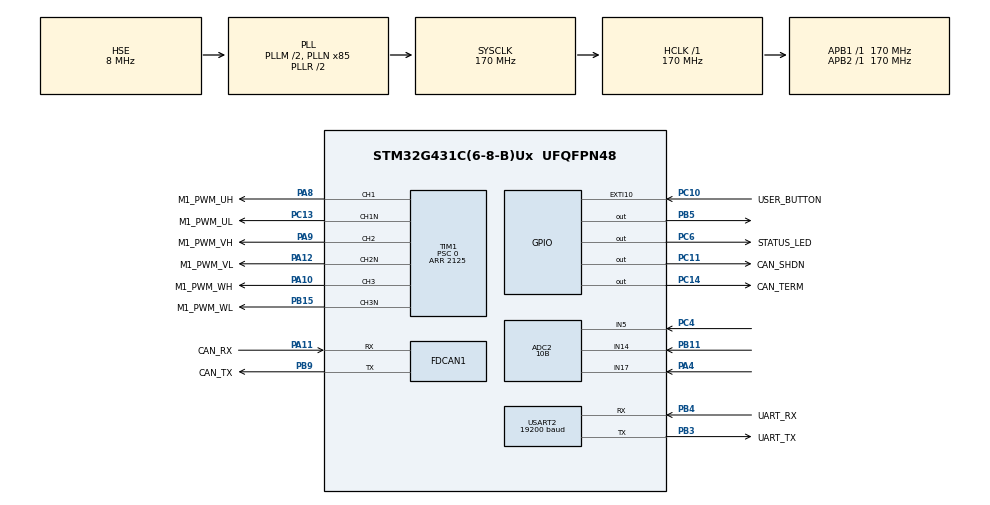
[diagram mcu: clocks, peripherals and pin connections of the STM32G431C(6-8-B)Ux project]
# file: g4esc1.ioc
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ADC2.Channel-0\#ChannelRegularConversion=ADC_CHANNEL_17
ADC2.Channel-1\#ChannelRegularConversion=ADC_CHANNEL_5
ADC2.Channel-2\#ChannelRegularConversion=ADC_CHANNEL_14
ADC2.ContinuousConvMode=ENABLE
ADC2.DMAContinuousRequests=ENABLE
ADC2.EOCSelection=ADC_EOC_SEQ_CONV
ADC2.NbrOfConversion=3
ADC2.NbrOfConversionFlag=1
ADC2.OffsetNumber-0\#ChannelRegularConversion=ADC_OFFSET_NONE
ADC2.OffsetNumber-1\#ChannelRegularConversion=ADC_OFFSET_NONE
ADC2.OffsetNumber-2\#ChannelRegularConversion=ADC_OFFSET_NONE
ADC2.Rank-0\#ChannelRegularConversion=1
ADC2.Rank-1\#ChannelRegularConversion=2
ADC2.Rank-2\#ChannelRegularConversion=3
ADC2.Resolution=ADC_RESOLUTION_10B
ADC2.SamplingTime-0\#ChannelRegularConversion=ADC_SAMPLETIME_12CYCLES_5
ADC2.SamplingTime-1\#ChannelRegularConversion=ADC_SAMPLETIME_12CYCLES_5
ADC2.SamplingTime-2\#ChannelRegularConversion=ADC_SAMPLETIME_12CYCLES_5
Dma.ADC2.2.Direction=DMA_PERIPH_TO_MEMORY
Dma.ADC2.2.EventEnable=DISABLE
Dma.ADC2.2.Instance=DMA1_Channel3
Dma.ADC2.2.MemDataAlignment=DMA_MDATAALIGN_HALFWORD
Dma.ADC2.2.MemInc=DMA_MINC_ENABLE
Dma.ADC2.2.Mode=DMA_CIRCULAR
Dma.ADC2.2.PeriphDataAlignment=DMA_PDATAALIGN_HALFWORD
Dma.ADC2.2.PeriphInc=DMA_PINC_DISABLE
Dma.ADC2.2.Polarity=HAL_DMAMUX_REQ_GEN_RISING
Dma.ADC2.2.Priority=DMA_PRIORITY_LOW
Dma.ADC2.2.RequestNumber=1
Dma.ADC2.2.SignalID=NONE
Dma.ADC2.2.SyncEnable=DISABLE
Dma.ADC2.2.SyncPolarity=HAL_DMAMUX_SYNC_NO_EVENT
Dma.ADC2.2.SyncRequestNumber=1
Dma.ADC2.2.SyncSignalID=NONE
Dma.Request0=USART2_RX
Dma.Request1=USART2_TX
Dma.Request2=ADC2
Dma.USART2_RX.0.Direction=DMA_PERIPH_TO_MEMORY
Dma.USART2_RX.0.EventEnable=DISABLE
Dma.USART2_RX.0.Instance=DMA1_Channel1
Dma.USART2_RX.0.MemDataAlignment=DMA_MDATAALIGN_BYTE
Dma.USART2_RX.0.MemInc=DMA_MINC_ENABLE
Dma.USART2_RX.0.Mode=DMA_CIRCULAR
Dma.USART2_RX.0.PeriphDataAlignment=DMA_PDATAALIGN_BYTE
Dma.USART2_RX.0.PeriphInc=DMA_PINC_DISABLE
Dma.USART2_RX.0.Polarity=HAL_DMAMUX_REQ_GEN_RISING
Dma.USART2_RX.0.Priority=DMA_PRIORITY_LOW
Dma.USART2_RX.0.RequestNumber=1
Dma.USART2_RX.0.SignalID=NONE
Dma.USART2_RX.0.SyncEnable=DISABLE
Dma.USART2_RX.0.SyncPolarity=HAL_DMAMUX_SYNC_NO_EVENT
Dma.USART2_RX.0.SyncRequestNumber=1
Dma.USART2_RX.0.SyncSignalID=NONE
Dma.USART2_TX.1.Direction=DMA_MEMORY_TO_PERIPH
Dma.USART2_TX.1.EventEnable=DISABLE
Dma.USART2_TX.1.Instance=DMA1_Channel2
Dma.USART2_TX.1.MemDataAlignment=DMA_MDATAALIGN_BYTE
Dma.USART2_TX.1.MemInc=DMA_MINC_ENABLE
Dma.USART2_TX.1.Mode=DMA_NORMAL
Dma.USART2_TX.1.PeriphDataAlignment=DMA_PDATAALIGN_BYTE
Dma.USART2_TX.1.PeriphInc=DMA_PINC_DISABLE
Dma.USART2_TX.1.Polarity=HAL_DMAMUX_REQ_GEN_RISING
Dma.USART2_TX.1.Priority=DMA_PRIORITY_LOW
Dma.USART2_TX.1.RequestNumber=1
Dma.USART2_TX.1.SignalID=NONE
Dma.USART2_TX.1.SyncEnable=DISABLE
Dma.USART2_TX.1.SyncPolarity=HAL_DMAMUX_SYNC_NO_EVENT
Dma.USART2_TX.1.SyncRequestNumber=1
Dma.USART2_TX.1.SyncSignalID=NONE
FDCAN1.AutoRetransmission=ENABLE
FDCAN1.CalculateBaudRateNominal=999999
FDCAN1.CalculateTimeBitNominal=1000
FDCAN1.CalculateTimeQuantumNominal=58.82352941176471
FDCAN1.NominalPrescaler=10
FDCAN1.NominalTimeSeg1=13
FDCAN1.NominalTimeSeg2=3
Mcu.Family=STM32G4
Mcu.Name=STM32G431C(6-8-B)Ux
Mcu.Package=UFQFPN48
NVIC.ADC1_2_IRQn=true\:0\:0\:false\:false\:true\:true\:true\:true
NVIC.DMA1_Channel1_IRQn=true\:3\:0\:true\:false\:true\:false\:true\:true
NVIC.DMA1_Channel2_IRQn=true\:3\:0\:true\:false\:true\:false\:true\:true
NVIC.DMA1_Channel3_IRQn=true\:0\:0\:false\:false\:true\:false\:true\:true
NVIC.EXTI15_10_IRQn=true\:4\:0\:true\:false\:true\:true\:true\:true
NVIC.FDCAN1_IT0_IRQn=true\:3\:0\:true\:false\:true\:true\:true\:true
NVIC.PriorityGroup=NVIC_PRIORITYGROUP_4
NVIC.TIM1_BRK_TIM15_IRQn=true\:1\:0\:true\:false\:true\:true\:true\:true
NVIC.TIM1_UP_TIM16_IRQn=true\:0\:0\:true\:false\:true\:true\:true\:true
NVIC.TIM6_DAC_IRQn=true\:3\:0\:true\:false\:true\:true\:true\:true
NVIC.USART2_IRQn=true\:3\:0\:true\:false\:true\:true\:true\:true
PA0.GPIO_Label=M1_BUS_VOLTAGE
PA0.Signal=ADC1_IN1
PA1.GPIO_Label=BEMF_U
PA1.Signal=SharedAnalog_PA1
PA10.GPIO_Label=M1_PWM_WH
PA10.GPIO_PuPd=GPIO_PULLDOWN
PA10.GPIO_Speed=GPIO_SPEED_FREQ_HIGH
PA10.Signal=S_TIM1_CH3
PA11.GPIO_Label=CAN_RX
PA11.Mode=FDCAN_Activate
PA11.Signal=FDCAN1_RX
PA12.GPIO_Label=M1_PWM_VL
PA12.GPIO_PuPd=GPIO_PULLDOWN
PA12.GPIO_Speed=GPIO_SPEED_FREQ_HIGH
PA12.Mode=PWM Generation2 CH2 CH2N
PA12.Signal=TIM1_CH2N
PA13.GPIO_Label=TMS
PA13.Mode=Serial_Wire
PA13.Signal=SYS_JTMS-SWDIO
PA14.GPIO_Label=TCK
PA14.Mode=Serial_Wire
PA14.Signal=SYS_JTCK-SWCLK
PA4.Mode=IN17-Single-Ended
PA4.Signal=ADC2_IN17
PA7.GPIO_Label=BEMF_V
PA7.Signal=SharedAnalog_PA7
PA8.GPIO_Label=M1_PWM_UH
PA8.GPIO_PuPd=GPIO_PULLDOWN
PA8.GPIO_Speed=GPIO_SPEED_FREQ_HIGH
PA8.Signal=S_TIM1_CH1
PA9.GPIO_Label=M1_PWM_VH
PA9.GPIO_PuPd=GPIO_PULLDOWN
PA9.GPIO_Speed=GPIO_SPEED_FREQ_HIGH
PA9.Signal=S_TIM1_CH2
PB0.GPIO_Label=BEMF_W
PB0.Signal=SharedAnalog_PB0
PB11.Mode=IN14-Single-Ended
PB11.Signal=ADC2_IN14
PB14.GPIO_Label=M1_TEMPERATURE
PB14.Signal=ADC1_IN5
PB15.GPIO_Label=M1_PWM_WL
PB15.GPIO_PuPd=GPIO_PULLDOWN
PB15.GPIO_Speed=GPIO_SPEED_FREQ_HIGH
PB15.Mode=PWM Generation3 CH3 CH3N
PB15.Signal=TIM1_CH3N
PB3.GPIO_Label=UART_TX
PB3.GPIO_Mode=GPIO_MODE_AF_PP
PB3.GPIO_PuPd=GPIO_NOPULL
PB3.GPIO_Speed=GPIO_SPEED_FREQ_LOW
PB3.Mode=Asynchronous
PB3.Signal=USART2_TX
PB4.GPIO_Label=UART_RX
PB4.GPIO_Mode=GPIO_MODE_AF_PP
PB4.GPIO_PuPd=GPIO_NOPULL
PB4.GPIO_Speed=GPIO_SPEED_FREQ_LOW
PB4.Mode=Asynchronous
PB4.Signal=USART2_RX
PB5.Signal=GPIO_Output
PB9.GPIO_Label=CAN_TX
PB9.Mode=FDCAN_Activate
PB9.Signal=FDCAN1_TX
PC10.GPIO_Label=USER_BUTTON
PC10.GPIO_ModeDefaultEXTI=GPIO_MODE_IT_FALLING
PC10.GPIO_PuPd=GPIO_NOPULL
PC10.Signal=GPXTI10
PC11.GPIO_Label=CAN_SHDN
PC11.Signal=GPIO_Output
PC13.GPIO_Label=M1_PWM_UL
PC13.GPIO_PuPd=GPIO_PULLDOWN
PC13.GPIO_Speed=GPIO_SPEED_FREQ_HIGH
PC13.Mode=PWM Generation1 CH1 CH1N
PC13.Signal=TIM1_CH1N
PC14-OSC32_IN.GPIO_Label=CAN_TERM
PC14-OSC32_IN.Signal=GPIO_Output
PC4.Mode=IN5-Single-Ended
PC4.Signal=ADC2_IN5
PC6.GPIO_Label=STATUS_LED
PC6.Signal=GPIO_Output
PF0-OSC_IN.Mode=HSE-External-Oscillator
PF0-OSC_IN.Signal=RCC_OSC_IN
PF1-OSC_OUT.Mode=HSE-External-Oscillator
PF1-OSC_OUT.Signal=RCC_OSC_OUT
ProjectManager.HeapSize=0x200
ProjectManager.StackSize=0x400
ProjectManager.TargetToolchain=STM32CubeIDE
RCC.ADC12CLockSelection=RCC_ADC12CLKSOURCE_PLL
RCC.ADC12Freq_Value=42500000
RCC.AHBFreq_Value=170000000
RCC.APB1Freq_Value=170000000
RCC.APB1TimFreq_Value=170000000
RCC.APB2Freq_Value=170000000
RCC.APB2TimFreq_Value=170000000
RCC.CK48CLockSelection=RCC_USBCLKSOURCE_PLL
RCC.CortexFreq_Value=170000000
RCC.EXTERNAL_CLOCK_VALUE=12288000
RCC.EnbaleCSS=true
RCC.HCLKFreq_Value=170000000
RCC.HSE_VALUE=8000000
RCC.HSI48_VALUE=48000000
RCC.HSI_VALUE=16000000
RCC.LSE_VALUE=32768
RCC.PLLM=RCC_PLLM_DIV2
RCC.PLLN=85
RCC.PLLP=RCC_PLLP_DIV8
RCC.PLLSourceVirtual=RCC_PLLSOURCE_HSE
RCC.PREFETCH_ENABLE=1
RCC.SYSCLKFreq_VALUE=170000000
RCC.SYSCLKSource=RCC_SYSCLKSOURCE_PLLCLK
RCC.USBFreq_Value=170000000
RCC.VCOOutputFreq_Value=340000000
SH.S_TIM1_CH1.0=TIM1_CH1,PWM Generation1 CH1 CH1N
SH.S_TIM1_CH2.0=TIM1_CH2,PWM Generation2 CH2 CH2N
SH.S_TIM1_CH3.0=TIM1_CH3,PWM Generation3 CH3 CH3N
SH.SharedAnalog_PA1.0=COMP1_INP
SH.SharedAnalog_PA7.0=COMP2_INP
SH.SharedAnalog_PB0.0=COMP4_INP
TIM1.AutoReloadPreload=TIM_AUTORELOAD_PRELOAD_DISABLE
TIM1.AutomaticOutput=TIM_AUTOMATICOUTPUT_DISABLE
TIM1.Break2Filter=3
TIM1.Break2Polarity=TIM_BREAK2POLARITY_HIGH
TIM1.Break2State=TIM_BREAK2_DISABLE
TIM1.BreakFilter=3
TIM1.BreakPolarity=TIM_BREAKPOLARITY_HIGH
TIM1.BreakState=TIM_BREAK_ENABLE
TIM1.Channel=TIM_CHANNEL_4
TIM1.Channel-PWM\ Generation1\ CH1\ CH1N=TIM_CHANNEL_1
TIM1.Channel-PWM\ Generation2\ CH2\ CH2N=TIM_CHANNEL_2
TIM1.Channel-PWM\ Generation3\ CH3\ CH3N=TIM_CHANNEL_3
TIM1.Channel-PWM\ Generation4\ No\ Output=TIM_CHANNEL_4
TIM1.ClearInputSource=TIM_CLEARINPUTSOURCE_NONE
TIM1.ClockDivision=TIM_CLOCKDIVISION_DIV2
TIM1.CounterMode=TIM_COUNTERMODE_CENTERALIGNED1
TIM1.DeadTime=68
TIM1.LockLevel=TIM_LOCKLEVEL_OFF
TIM1.OC1Preload_PWM=ENABLE
TIM1.OC2Preload_PWM=ENABLE
TIM1.OC3Preload_PWM=ENABLE
TIM1.OC4Preload_PWM=ENABLE
TIM1.OCFastMode_PWM=TIM_OCFAST_DISABLE
TIM1.OCIdleState_1=TIM_OCIDLESTATE_RESET
TIM1.OCIdleState_2=TIM_OCIDLESTATE_RESET
TIM1.OCIdleState_3=TIM_OCIDLESTATE_RESET
TIM1.OCIdleState_4=TIM_OCIDLESTATE_RESET
TIM1.OCMode_PWM-PWM\ Generation1\ CH1\ CH1N=TIM_OCMODE_PWM1
TIM1.OCMode_PWM-PWM\ Generation2\ CH2\ CH2N=TIM_OCMODE_PWM1
TIM1.OCMode_PWM-PWM\ Generation3\ CH3\ CH3N=TIM_OCMODE_PWM1
TIM1.OCMode_PWM-PWM\ Generation4\ No\ Output=TIM_OCMODE_PWM2
TIM1.OCNIdleState_1=TIM_OCNIDLESTATE_RESET
TIM1.OCNIdleState_2=TIM_OCNIDLESTATE_RESET
TIM1.OCNIdleState_3=TIM_OCNIDLESTATE_RESET
TIM1.OCNPolarity_1=TIM_OCNPOLARITY_HIGH
TIM1.OCNPolarity_2=TIM_OCNPOLARITY_HIGH
TIM1.OCNPolarity_3=TIM_OCNPOLARITY_HIGH
TIM1.OCPolarity_1=TIM_OCPOLARITY_HIGH
TIM1.OCPolarity_2=TIM_OCPOLARITY_HIGH
TIM1.OCPolarity_3=TIM_OCPOLARITY_HIGH
TIM1.OCPolarity_4=TIM_OCPOLARITY_HIGH
TIM1.OffStateIDLEMode=TIM_OSSI_ENABLE
TIM1.OffStateRunMode=TIM_OSSR_ENABLE
TIM1.PeriodNoDither=2125
TIM1.Prescaler=0
TIM1.PulseNoDither_1=0
TIM1.PulseNoDither_2=0
TIM1.PulseNoDither_3=0
TIM1.PulseNoDither_4=1
TIM1.RepetitionCounter=1
TIM1.SourceBRK2DigInput=TIM_BREAKINPUTSOURCE_DISABLE
TIM1.SourceBRKCOMP1=TIM_BREAKINPUTSOURCE_DISABLE
TIM1.SourceBRKCOMP2=TIM_BREAKINPUTSOURCE_DISABLE
TIM1.SourceBRKCOMP4=TIM_BREAKINPUTSOURCE_DISABLE
TIM1.SourceBRKDigInput=TIM_BREAKINPUTSOURCE_DISABLE
TIM1.TIM_MasterOutputTrigger=TIM_TRGO_OC4REF
TIM1.TIM_MasterOutputTrigger2=TIM_TRGO2_RESET
TIM6.Period=999
TIM6.Prescaler=169
USART2.BaudRate=19200
USART2.VirtualMode-Asynchronous=VM_ASYNC
USART2.WordLength=WORDLENGTH_8B
VP_SYS_VS_DBSignals.Mode=DisableDeadBatterySignals
VP_TIM1_VS_ClockSourceINT.Mode=Internal
VP_TIM1_VS_no_output4.Mode=PWM Generation4 No Output
VP_TIM6_VS_ClockSourceINT.Mode=Enable_Timer
board=custom

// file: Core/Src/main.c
/* USER CODE BEGIN Header */
/**
  ******************************************************************************
  * @file           : main.c
  * @brief          : Main program body
  ******************************************************************************
  * @attention
  *
  * Copyright (c) 2026 STMicroelectronics.
  * All rights reserved.
  *
  * This software is licensed under terms that can be found in the LICENSE file
  * in the root directory of this software component.
  * If no LICENSE file comes with this software, it is provided AS-IS.
  *
  ******************************************************************************
  */
/* USER CODE END Header */
#include "main.h"

/* USER CODE BEGIN Includes */
#include <platform.h>
/* USER CODE END Includes */

ADC_HandleTypeDef hadc2;
DMA_HandleTypeDef hdma_adc2;

FDCAN_HandleTypeDef hfdcan1;

TIM_HandleTypeDef htim1;
TIM_HandleTypeDef htim6;

UART_HandleTypeDef huart2;
DMA_HandleTypeDef hdma_usart2_rx;
DMA_HandleTypeDef hdma_usart2_tx;

void SystemClock_Config(void);
static void MX_GPIO_Init(void);
static void MX_DMA_Init(void);
static void MX_FDCAN1_Init(void);
static void MX_TIM1_Init(void);
static void MX_TIM6_Init(void);
static void MX_USART2_UART_Init(void);
static void MX_ADC2_Init(void);

int main(void)
{

  /* MCU Configuration--------------------------------------------------------*/

  /* Reset of all peripherals, Initializes the Flash interface and the Systick. */
  HAL_Init();

  /* Configure the system clock */
  SystemClock_Config();

  /* Initialize all configured peripherals */
  MX_GPIO_Init();
  MX_DMA_Init();
  MX_FDCAN1_Init();
  MX_TIM1_Init();
  MX_TIM6_Init();
  MX_USART2_UART_Init();
  MX_ADC2_Init();
  /* USER CODE BEGIN 2 */
  platform_setup();
  /* USER CODE END 2 */

  /* Infinite loop */
  while (1)
  {

  }
}

void SystemClock_Config(void)
{
  RCC_OscInitTypeDef RCC_OscInitStruct = {0};
  RCC_ClkInitTypeDef RCC_ClkInitStruct = {0};

  /** Configure the main internal regulator output voltage
  */
  HAL_PWREx_ControlVoltageScaling(PWR_REGULATOR_VOLTAGE_SCALE1_BOOST);

  /** Initializes the RCC Oscillators according to the specified parameters
  * in the RCC_OscInitTypeDef structure.
  */
  RCC_OscInitStruct.OscillatorType = RCC_OSCILLATORTYPE_HSE;
  RCC_OscInitStruct.HSEState = RCC_HSE_ON;
  RCC_OscInitStruct.PLL.PLLState = RCC_PLL_ON;
  RCC_OscInitStruct.PLL.PLLSource = RCC_PLLSOURCE_HSE;
  RCC_OscInitStruct.PLL.PLLM = RCC_PLLM_DIV2;
  RCC_OscInitStruct.PLL.PLLN = 85;
  RCC_OscInitStruct.PLL.PLLP = RCC_PLLP_DIV8;
  RCC_OscInitStruct.PLL.PLLQ = RCC_PLLQ_DIV2;
  RCC_OscInitStruct.PLL.PLLR = RCC_PLLR_DIV2;
  if (HAL_RCC_OscConfig(&RCC_OscInitStruct) != HAL_OK)
  {
    Error_Handler();
  }

  /** Initializes the CPU, AHB and APB buses clocks
  */
  RCC_ClkInitStruct.ClockType = RCC_CLOCKTYPE_HCLK|RCC_CLOCKTYPE_SYSCLK
                              |RCC_CLOCKTYPE_PCLK1|RCC_CLOCKTYPE_PCLK2;
  RCC_ClkInitStruct.SYSCLKSource = RCC_SYSCLKSOURCE_PLLCLK;
  RCC_ClkInitStruct.AHBCLKDivider = RCC_SYSCLK_DIV1;
  RCC_ClkInitStruct.APB1CLKDivider = RCC_HCLK_DIV1;
  RCC_ClkInitStruct.APB2CLKDivider = RCC_HCLK_DIV1;

  if (HAL_RCC_ClockConfig(&RCC_ClkInitStruct, FLASH_LATENCY_4) != HAL_OK)
  {
    Error_Handler();
  }

  /** Enables the Clock Security System
  */
  HAL_RCC_EnableCSS();
}

static void MX_ADC2_Init(void)
{

  ADC_ChannelConfTypeDef sConfig = {0};

  /** Common config
  */
  hadc2.Instance = ADC2;
  hadc2.Init.ClockPrescaler = ADC_CLOCK_SYNC_PCLK_DIV4;
  hadc2.Init.Resolution = ADC_RESOLUTION_10B;
  hadc2.Init.DataAlign = ADC_DATAALIGN_RIGHT;
  hadc2.Init.GainCompensation = 0;
  hadc2.Init.ScanConvMode = ADC_SCAN_ENABLE;
  hadc2.Init.EOCSelection = ADC_EOC_SEQ_CONV;
  hadc2.Init.LowPowerAutoWait = DISABLE;
  hadc2.Init.ContinuousConvMode = ENABLE;
  hadc2.Init.NbrOfConversion = 3;
  hadc2.Init.DiscontinuousConvMode = DISABLE;
  hadc2.Init.ExternalTrigConv = ADC_SOFTWARE_START;
  hadc2.Init.ExternalTrigConvEdge = ADC_EXTERNALTRIGCONVEDGE_NONE;
  hadc2.Init.DMAContinuousRequests = ENABLE;
  hadc2.Init.Overrun = ADC_OVR_DATA_PRESERVED;
  hadc2.Init.OversamplingMode = DISABLE;
  if (HAL_ADC_Init(&hadc2) != HAL_OK)
  {
    Error_Handler();
  }

  /** Configure Regular Channel
  */
  sConfig.Channel = ADC_CHANNEL_17;
  sConfig.Rank = ADC_REGULAR_RANK_1;
  sConfig.SamplingTime = ADC_SAMPLETIME_12CYCLES_5;
  sConfig.SingleDiff = ADC_SINGLE_ENDED;
  sConfig.OffsetNumber = ADC_OFFSET_NONE;
  sConfig.Offset = 0;
  if (HAL_ADC_ConfigChannel(&hadc2, &sConfig) != HAL_OK)
  {
    Error_Handler();
  }

  /** Configure Regular Channel
  */
  sConfig.Channel = ADC_CHANNEL_5;
  sConfig.Rank = ADC_REGULAR_RANK_2;
  if (HAL_ADC_ConfigChannel(&hadc2, &sConfig) != HAL_OK)
  {
    Error_Handler();
  }

  /** Configure Regular Channel
  */
  sConfig.Channel = ADC_CHANNEL_14;
  sConfig.Rank = ADC_REGULAR_RANK_3;
  if (HAL_ADC_ConfigChannel(&hadc2, &sConfig) != HAL_OK)
  {
    Error_Handler();
  }

}

static void MX_FDCAN1_Init(void)
{

  hfdcan1.Instance = FDCAN1;
  hfdcan1.Init.ClockDivider = FDCAN_CLOCK_DIV1;
  hfdcan1.Init.FrameFormat = FDCAN_FRAME_CLASSIC;
  hfdcan1.Init.Mode = FDCAN_MODE_NORMAL;
  hfdcan1.Init.AutoRetransmission = ENABLE;
  hfdcan1.Init.TransmitPause = DISABLE;
  hfdcan1.Init.ProtocolException = DISABLE;
  hfdcan1.Init.NominalPrescaler = 10;
  hfdcan1.Init.NominalSyncJumpWidth = 1;
  hfdcan1.Init.NominalTimeSeg1 = 13;
  hfdcan1.Init.NominalTimeSeg2 = 3;
  hfdcan1.Init.DataPrescaler = 1;
  hfdcan1.Init.DataSyncJumpWidth = 1;
  hfdcan1.Init.DataTimeSeg1 = 1;
  hfdcan1.Init.DataTimeSeg2 = 1;
  hfdcan1.Init.StdFiltersNbr = 0;
  hfdcan1.Init.ExtFiltersNbr = 0;
  hfdcan1.Init.TxFifoQueueMode = FDCAN_TX_FIFO_OPERATION;
  if (HAL_FDCAN_Init(&hfdcan1) != HAL_OK)
  {
    Error_Handler();
  }

}

static void MX_TIM1_Init(void)
{

  TIM_ClockConfigTypeDef sClockSourceConfig = {0};
  TIM_MasterConfigTypeDef sMasterConfig = {0};
  TIM_OC_InitTypeDef sConfigOC = {0};
  TIM_BreakDeadTimeConfigTypeDef sBreakDeadTimeConfig = {0};

  htim1.Instance = TIM1;
  htim1.Init.Prescaler = 0;
  htim1.Init.CounterMode = TIM_COUNTERMODE_CENTERALIGNED1;
  htim1.Init.Period = 2125;
  htim1.Init.ClockDivision = TIM_CLOCKDIVISION_DIV2;
  htim1.Init.RepetitionCounter = 1;
  htim1.Init.AutoReloadPreload = TIM_AUTORELOAD_PRELOAD_DISABLE;
  if (HAL_TIM_Base_Init(&htim1) != HAL_OK)
  {
    Error_Handler();
  }
  sClockSourceConfig.ClockSource = TIM_CLOCKSOURCE_INTERNAL;
  if (HAL_TIM_ConfigClockSource(&htim1, &sClockSourceConfig) != HAL_OK)
  {
    Error_Handler();
  }
  if (HAL_TIM_PWM_Init(&htim1) != HAL_OK)
  {
    Error_Handler();
  }
  sMasterConfig.MasterOutputTrigger = TIM_TRGO_OC4REF;
  sMasterConfig.MasterOutputTrigger2 = TIM_TRGO2_RESET;
  sMasterConfig.MasterSlaveMode = TIM_MASTERSLAVEMODE_DISABLE;
  if (HAL_TIMEx_MasterConfigSynchronization(&htim1, &sMasterConfig) != HAL_OK)
  {
    Error_Handler();
  }
  sConfigOC.OCMode = TIM_OCMODE_PWM1;
  sConfigOC.Pulse = 0;
  sConfigOC.OCPolarity = TIM_OCPOLARITY_HIGH;
  sConfigOC.OCNPolarity = TIM_OCNPOLARITY_HIGH;
  sConfigOC.OCFastMode = TIM_OCFAST_DISABLE;
  sConfigOC.OCIdleState = TIM_OCIDLESTATE_RESET;
  sConfigOC.OCNIdleState = TIM_OCNIDLESTATE_RESET;
  if (HAL_TIM_PWM_ConfigChannel(&htim1, &sConfigOC, TIM_CHANNEL_1) != HAL_OK)
  {
    Error_Handler();
  }
  if (HAL_TIM_PWM_ConfigChannel(&htim1, &sConfigOC, TIM_CHANNEL_2) != HAL_OK)
  {
    Error_Handler();
  }
  if (HAL_TIM_PWM_ConfigChannel(&htim1, &sConfigOC, TIM_CHANNEL_3) != HAL_OK)
  {
    Error_Handler();
  }
  sConfigOC.OCMode = TIM_OCMODE_PWM2;
  sConfigOC.Pulse = 1;
  if (HAL_TIM_PWM_ConfigChannel(&htim1, &sConfigOC, TIM_CHANNEL_4) != HAL_OK)
  {
    Error_Handler();
  }
  sBreakDeadTimeConfig.OffStateRunMode = TIM_OSSR_ENABLE;
  sBreakDeadTimeConfig.OffStateIDLEMode = TIM_OSSI_ENABLE;
  sBreakDeadTimeConfig.LockLevel = TIM_LOCKLEVEL_OFF;
  sBreakDeadTimeConfig.DeadTime = 68;
  sBreakDeadTimeConfig.BreakState = TIM_BREAK_ENABLE;
  sBreakDeadTimeConfig.BreakPolarity = TIM_BREAKPOLARITY_HIGH;
  sBreakDeadTimeConfig.BreakFilter = 3;
  sBreakDeadTimeConfig.BreakAFMode = TIM_BREAK_AFMODE_INPUT;
  sBreakDeadTimeConfig.Break2State = TIM_BREAK2_DISABLE;
  sBreakDeadTimeConfig.Break2Polarity = TIM_BREAK2POLARITY_HIGH;
  sBreakDeadTimeConfig.Break2Filter = 3;
  sBreakDeadTimeConfig.Break2AFMode = TIM_BREAK_AFMODE_INPUT;
  sBreakDeadTimeConfig.AutomaticOutput = TIM_AUTOMATICOUTPUT_DISABLE;
  if (HAL_TIMEx_ConfigBreakDeadTime(&htim1, &sBreakDeadTimeConfig) != HAL_OK)
  {
    Error_Handler();
  }
  HAL_TIM_MspPostInit(&htim1);

}

static void MX_TIM6_Init(void)
{

  TIM_MasterConfigTypeDef sMasterConfig = {0};

  htim6.Instance = TIM6;
  htim6.Init.Prescaler = 169;
  htim6.Init.CounterMode = TIM_COUNTERMODE_UP;
  htim6.Init.Period = 999;
  htim6.Init.AutoReloadPreload = TIM_AUTORELOAD_PRELOAD_DISABLE;
  if (HAL_TIM_Base_Init(&htim6) != HAL_OK)
  {
    Error_Handler();
  }
  sMasterConfig.MasterOutputTrigger = TIM_TRGO_RESET;
  sMasterConfig.MasterSlaveMode = TIM_MASTERSLAVEMODE_DISABLE;
  if (HAL_TIMEx_MasterConfigSynchronization(&htim6, &sMasterConfig) != HAL_OK)
  {
    Error_Handler();
  }

}

static void MX_USART2_UART_Init(void)
{

  huart2.Instance = USART2;
  huart2.Init.BaudRate = 19200;
  huart2.Init.WordLength = UART_WORDLENGTH_8B;
  huart2.Init.StopBits = UART_STOPBITS_1;
  huart2.Init.Parity = UART_PARITY_NONE;
  huart2.Init.Mode = UART_MODE_TX_RX;
  huart2.Init.HwFlowCtl = UART_HWCONTROL_NONE;
  huart2.Init.OverSampling = UART_OVERSAMPLING_16;
  huart2.Init.OneBitSampling = UART_ONE_BIT_SAMPLE_DISABLE;
  huart2.Init.ClockPrescaler = UART_PRESCALER_DIV1;
  huart2.AdvancedInit.AdvFeatureInit = UART_ADVFEATURE_NO_INIT;
  if (HAL_UART_Init(&huart2) != HAL_OK)
  {
    Error_Handler();
  }
  if (HAL_UARTEx_SetTxFifoThreshold(&huart2, UART_TXFIFO_THRESHOLD_1_8) != HAL_OK)
  {
    Error_Handler();
  }
  if (HAL_UARTEx_SetRxFifoThreshold(&huart2, UART_RXFIFO_THRESHOLD_1_8) != HAL_OK)
  {
    Error_Handler();
  }
  if (HAL_UARTEx_DisableFifoMode(&huart2) != HAL_OK)
  {
    Error_Handler();
  }

}

static void MX_DMA_Init(void)
{

  /* DMA controller clock enable */
  __HAL_RCC_DMAMUX1_CLK_ENABLE();
  __HAL_RCC_DMA1_CLK_ENABLE();

  /* DMA interrupt init */
  /* DMA1_Channel1_IRQn interrupt configuration */
  HAL_NVIC_SetPriority(DMA1_Channel1_IRQn, 3, 0);
  HAL_NVIC_EnableIRQ(DMA1_Channel1_IRQn);
  /* DMA1_Channel2_IRQn interrupt configuration */
  HAL_NVIC_SetPriority(DMA1_Channel2_IRQn, 3, 0);
  HAL_NVIC_EnableIRQ(DMA1_Channel2_IRQn);
  /* DMA1_Channel3_IRQn interrupt configuration */
  HAL_NVIC_SetPriority(DMA1_Channel3_IRQn, 0, 0);
  HAL_NVIC_EnableIRQ(DMA1_Channel3_IRQn);

}

static void MX_GPIO_Init(void)
{
  GPIO_InitTypeDef GPIO_InitStruct = {0};

  /* GPIO Ports Clock Enable */
  __HAL_RCC_GPIOC_CLK_ENABLE();
  __HAL_RCC_GPIOF_CLK_ENABLE();
  __HAL_RCC_GPIOA_CLK_ENABLE();
  __HAL_RCC_GPIOB_CLK_ENABLE();

  /*Configure GPIO pin Output Level */
  HAL_GPIO_WritePin(GPIOC, CAN_TERM_Pin|STATUS_LED_Pin|CAN_SHDN_Pin, GPIO_PIN_RESET);

  /*Configure GPIO pin Output Level */
  HAL_GPIO_WritePin(GPIOB, GPIO_PIN_5, GPIO_PIN_RESET);

  /*Configure GPIO pins : CAN_TERM_Pin STATUS_LED_Pin CAN_SHDN_Pin */
  GPIO_InitStruct.Pin = CAN_TERM_Pin|STATUS_LED_Pin|CAN_SHDN_Pin;
  GPIO_InitStruct.Mode = GPIO_MODE_OUTPUT_PP;
  GPIO_InitStruct.Pull = GPIO_NOPULL;
  GPIO_InitStruct.Speed = GPIO_SPEED_FREQ_LOW;
  HAL_GPIO_Init(GPIOC, &GPIO_InitStruct);

  /*Configure GPIO pins : M1_BUS_VOLTAGE_Pin BEMF_U_Pin BEMF_V_Pin */
  GPIO_InitStruct.Pin = M1_BUS_VOLTAGE_Pin|BEMF_U_Pin|BEMF_V_Pin;
  GPIO_InitStruct.Mode = GPIO_MODE_ANALOG;
  GPIO_InitStruct.Pull = GPIO_NOPULL;
  HAL_GPIO_Init(GPIOA, &GPIO_InitStruct);

  /*Configure GPIO pins : BEMF_W_Pin M1_TEMPERATURE_Pin */
  GPIO_InitStruct.Pin = BEMF_W_Pin|M1_TEMPERATURE_Pin;
  GPIO_InitStruct.Mode = GPIO_MODE_ANALOG;
  GPIO_InitStruct.Pull = GPIO_NOPULL;
  HAL_GPIO_Init(GPIOB, &GPIO_InitStruct);

  /*Configure GPIO pin : USER_BUTTON_Pin */
  GPIO_InitStruct.Pin = USER_BUTTON_Pin;
  GPIO_InitStruct.Mode = GPIO_MODE_IT_FALLING;
  GPIO_InitStruct.Pull = GPIO_NOPULL;
  HAL_GPIO_Init(USER_BUTTON_GPIO_Port, &GPIO_InitStruct);

  /*Configure GPIO pin : PB5 */
  GPIO_InitStruct.Pin = GPIO_PIN_5;
  GPIO_InitStruct.Mode = GPIO_MODE_OUTPUT_PP;
  GPIO_InitStruct.Pull = GPIO_NOPULL;
  GPIO_InitStruct.Speed = GPIO_SPEED_FREQ_LOW;
  HAL_GPIO_Init(GPIOB, &GPIO_InitStruct);

  /* EXTI interrupt init*/
  HAL_NVIC_SetPriority(EXTI15_10_IRQn, 4, 0);
  HAL_NVIC_EnableIRQ(EXTI15_10_IRQn);

}

void Error_Handler(void)
{
  __disable_irq();
  while (1)
  {
  }
}
